AUTOSAR XML (schema 4-0-3)
standard types defined: Boolean, UInt32
package /AUTOSAR_Platform/DataConstrs
  range DC_Boolean: raw 0..1
package /PATAC/MSM/ComponentTypes
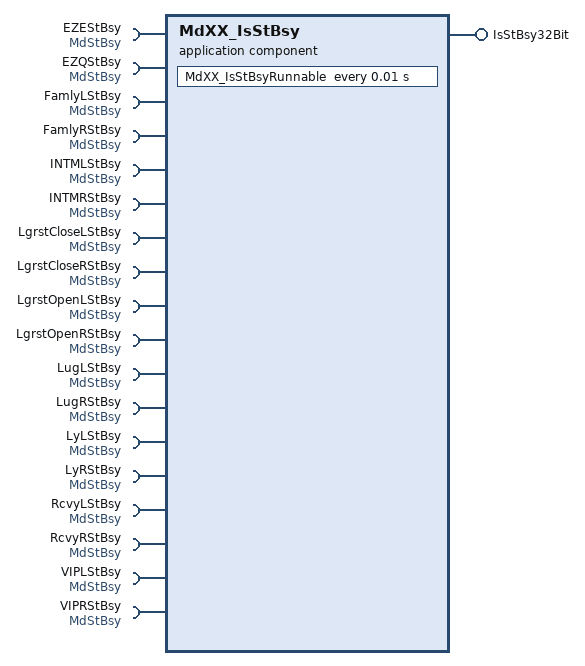
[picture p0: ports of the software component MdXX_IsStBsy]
  application sw component type MdXX_IsStBsy
    provide port IsStBsy32Bit: nonqueued-sender-com-spec{data-element=IsStBsy32Bit/Val, init-value=0}, provided-interface=IsStBsy32Bit
    18 x require port, all with nonqueued-receiver-com-spec{data-element=MdStBsy/Val, filter=data-filter-type=ALWAYS, init-value=0}, required-interface=MdStBsy:
      EZEStBsy
      EZQStBsy
      FamlyLStBsy
      FamlyRStBsy
      INTMLStBsy
      INTMRStBsy
      LgrstCloseLStBsy
      LgrstCloseRStBsy
      LgrstOpenLStBsy
      LgrstOpenRStBsy
      LugLStBsy
      LugRStBsy
      LyLStBsy
      LyRStBsy
      RcvyLStBsy
      RcvyRStBsy
      VIPLStBsy
      VIPRStBsy
    behavior MdXX_IsStBsy_InternalBehavior
      timing event TMT_MdXX_IsStBsyRunnable: start-on-event=MdXX_IsStBsyRunnable, period=0.01
      runnable MdXX_IsStBsyRunnable
        data-receive-point-by-arguments:
          18 x access:
            REC_EZEStBsy_Val: accessed-variable=EZEStBsy.Val
            REC_EZQStBsy_Val: accessed-variable=EZQStBsy.Val
            REC_FamlyLStBsy_Val: accessed-variable=FamlyLStBsy.Val
            REC_FamlyRStBsy_Val: accessed-variable=FamlyRStBsy.Val
            REC_INTMLStBsy_Val: accessed-variable=INTMLStBsy.Val
            REC_INTMRStBsy_Val: accessed-variable=INTMRStBsy.Val
            REC_LgrstCloseLStBsy_Val: accessed-variable=LgrstCloseLStBsy.Val
            REC_LgrstCloseRStBsy_Val: accessed-variable=LgrstCloseRStBsy.Val
            REC_LgrstOpenLStBsy_Val: accessed-variable=LgrstOpenLStBsy.Val
            REC_LgrstOpenRStBsy_Val: accessed-variable=LgrstOpenRStBsy.Val
            REC_LugLStBsy_Val: accessed-variable=LugLStBsy.Val
            REC_LugRStBsy_Val: accessed-variable=LugRStBsy.Val
            REC_LyLStBsy_Val: accessed-variable=LyLStBsy.Val
            REC_LyRStBsy_Val: accessed-variable=LyRStBsy.Val
            REC_RcvyLStBsy_Val: accessed-variable=RcvyLStBsy.Val
            REC_RcvyRStBsy_Val: accessed-variable=RcvyRStBsy.Val
            REC_VIPLStBsy_Val: accessed-variable=VIPLStBsy.Val
            REC_VIPRStBsy_Val: accessed-variable=VIPRStBsy.Val
        data-send-points:
          access SEND_StBsy32Bit_Val: accessed-variable=IsStBsy32Bit.Val
  swc implementation MdXX_IsStBsy_Implementation: behavior=MdXX_IsStBsy_InternalBehavior
    code-descriptors:
      code Default: artifact-descriptors=autosar-engineering-object={short-label=Default, category=SWSRC}
package /PATAC/MSM/ModeAdjust/PortInterface
  sender receiver interface IsStBsy32Bit: invalidation-policy{data-element=IsStBsy32Bit/Val, handle-invalid=DONT-INVALIDATE}
    data Val: type=UInt32
  sender receiver interface MdStBsy: invalidation-policy{data-element=MdStBsy/Val, handle-invalid=DONT-INVALIDATE}
    data Val: type=Boolean
